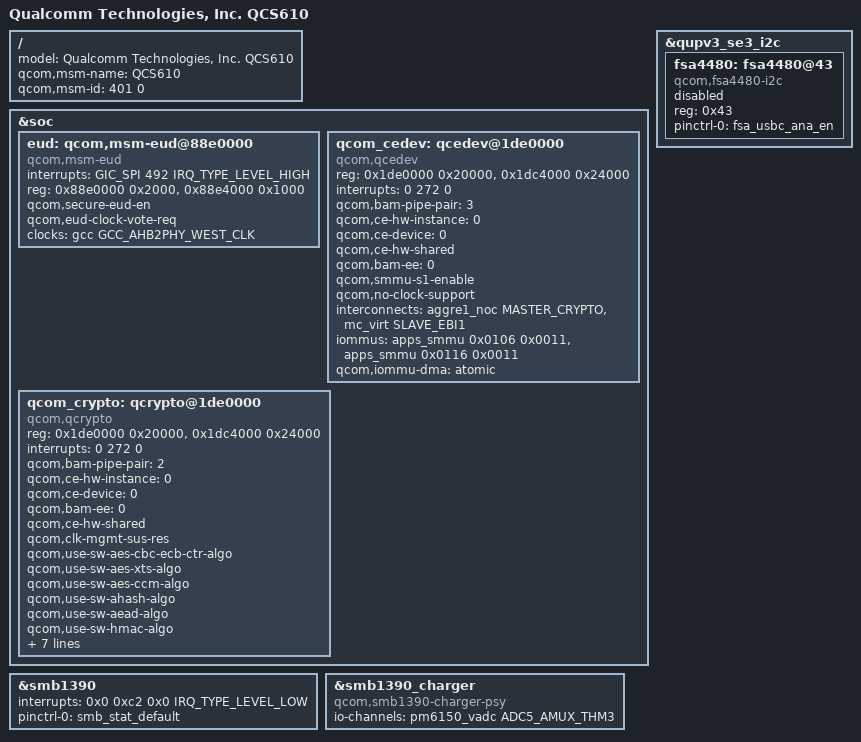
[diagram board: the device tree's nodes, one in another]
#include "sm6150.dtsi"
#include "display/sm6150-sde-display.dtsi"
#include "sm6150-pmic-overlay.dtsi"
/ {
	model = "Qualcomm Technologies, Inc. QCS610";
	qcom,msm-name = "QCS610";
	qcom,msm-id = <401 0>;
};

&soc {
	eud: qcom,msm-eud@88e0000 {
		compatible = "qcom,msm-eud";
		interrupt-names = "eud_irq";
		interrupts = <GIC_SPI 492 IRQ_TYPE_LEVEL_HIGH>;
		reg = <0x88e0000 0x2000>,
		      <0x88e4000 0x1000>;
		reg-names = "eud_base", "eud_mode_mgr2";
		qcom,secure-eud-en;
		qcom,eud-clock-vote-req;
		clocks = <&gcc GCC_AHB2PHY_WEST_CLK>;
		clock-names = "eud_ahb2phy_clk";
		status = "ok";
	};

	qcom_cedev: qcedev@1de0000 {
		compatible = "qcom,qcedev";
		reg = <0x1de0000 0x20000>,
			<0x1dc4000 0x24000>;
		reg-names = "crypto-base","crypto-bam-base";
		interrupts = <0 272 0>;
		qcom,bam-pipe-pair = <3>;
		qcom,ce-hw-instance = <0>;
		qcom,ce-device = <0>;
		qcom,ce-hw-shared;
		qcom,bam-ee = <0>;
		qcom,smmu-s1-enable;
		qcom,no-clock-support;
		interconnect-names = "data_path";
		interconnects = <&aggre1_noc MASTER_CRYPTO &mc_virt SLAVE_EBI1>;
		iommus = <&apps_smmu 0x0106 0x0011>,
			 <&apps_smmu 0x0116 0x0011>;
		qcom,iommu-dma = "atomic";
	};

	qcom_crypto: qcrypto@1de0000 {
		compatible = "qcom,qcrypto";
		reg = <0x1de0000 0x20000>,
			 <0x1dc4000 0x24000>;
		reg-names = "crypto-base","crypto-bam-base";
		interrupts = <0 272 0>;
		qcom,bam-pipe-pair = <2>;
		qcom,ce-hw-instance = <0>;
		qcom,ce-device = <0>;
		qcom,bam-ee = <0>;
		qcom,ce-hw-shared;
		qcom,clk-mgmt-sus-res;
		qcom,use-sw-aes-cbc-ecb-ctr-algo;
		qcom,use-sw-aes-xts-algo;
		qcom,use-sw-aes-ccm-algo;
		qcom,use-sw-ahash-algo;
		qcom,use-sw-aead-algo;
		qcom,use-sw-hmac-algo;
		qcom,smmu-s1-enable;
		qcom,no-clock-support;
		interconnect-names = "data_path";
		interconnects = <&aggre1_noc MASTER_CRYPTO &mc_virt SLAVE_EBI1>;
		iommus = <&apps_smmu 0x0104 0x0011>,
			 <&apps_smmu 0x0114 0x0011>;
		qcom,iommu-dma = "atomic";
	};
};

&qupv3_se3_i2c {
	status = "ok";
	#include "smb1390.dtsi"

	fsa4480: fsa4480@43 {
		compatible = "qcom,fsa4480-i2c";
		reg = <0x43>;
		pinctrl-names = "default";
		pinctrl-0 = <&fsa_usbc_ana_en>;
		status = "disabled";
	};
};

&smb1390 {
	/delete-property/ interrupts;
	interrupts = <0x0 0xc2 0x0 IRQ_TYPE_LEVEL_LOW>;
	pinctrl-names = "default";
	pinctrl-0 = <&smb_stat_default>;
	status = "ok";
};

&smb1390_charger {
	/delete-property/ compatible;
	compatible = "qcom,smb1390-charger-psy";
	io-channels = <&pm6150_vadc ADC5_AMUX_THM3>;
	io-channel-names = "cp_die_temp";
	status = "ok";
};
